# LPC5411x register map
Vendor: nxp.com; File version: 1.2
CPU: CM4 r0p1, little endian, MPU, FPU, VTOR, vendor SysTick, 3 interrupt priority bits
Registers are 32-bit, read-write, reset 0x0 unless marked. A register's access mark holds for its fields unless they carry their own. Offsets are from the block's base; [hi:lo] are bit positions; 'fields as' and 'values as' point back to an identical list.

## USART0 — LPC5411x USARTs
Base 0x40086000
Same registers: USART1 0x40087000, USART2 0x40088000, USART3 0x40089000, USART4 0x4008A000, USART7 0x40096000, USART5 0x40096000, USART6 0x40096000
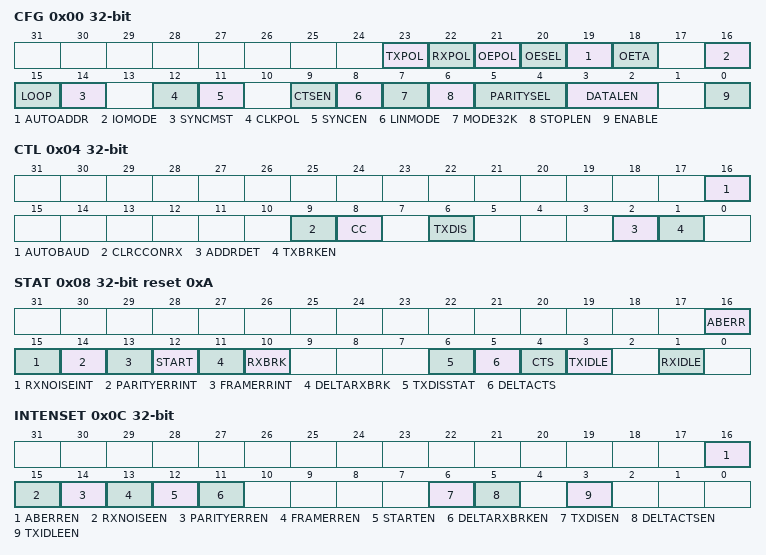
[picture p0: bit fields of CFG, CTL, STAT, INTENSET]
0x00 CFG — USART Configuration register. Basic USART configuration settings that typically are not changed during operation.
  [23] TXPOL — Transmit data polarity.
    0=STANDARD (Standard. The TX signal is sent out without change. This means that the TX rest value is 1, start bit is 0, data is not inverted, and the stop bit is 1.); 1=INVERTED (Inverted. The TX signal is inverted by the USART before being sent out. This means that the TX rest value is 0, start bit is 1, data is inverted, and the stop bit is 0.)
  [22] RXPOL — Receive data polarity.
    0=STANDARD (Standard. The RX signal is used as it arrives from the pin. This means that the RX rest value is 1, start bit is 0, data is not inverted, and the stop bit is 1.); 1=INVERTED (Inverted. The RX signal is inverted before being used by the USART. This means that the RX rest value is 0, start bit is 1, data is inverted, and the stop bit is 0.)
  [21] OEPOL — Output Enable Polarity.
    0=LOW (Low. If selected by OESEL, the output enable is active low.); 1=HIGH (High. If selected by OESEL, the output enable is active high.)
  [20] OESEL — Output Enable Select.
    0=STANDARD (Standard. The RTS signal is used as the standard flow control function.); 1=RS_485 (RS-485. The RTS signal configured to provide an output enable signal to control an RS-485 transceiver.)
  [19] AUTOADDR — Automatic Address matching enable.
    0=DISABLED (Disabled. When addressing is enabled by ADDRDET, address matching is done by software. This provides the possibility of versatile addressing (e.g. respond to more than one address).); 1=ENABLED (Enabled. When addressing is enabled by ADDRDET, address matching is done by hardware, using the value in the ADDR register as the address to match.)
  [18] OETA — Output Enable Turnaround time enable for RS-485 operation.
    0=DISABLED (Disabled. If selected by OESEL, the Output Enable signal deasserted at the end of the last stop bit of a transmission.); 1=ENABLED (Enabled. If selected by OESEL, the Output Enable signal remains asserted for one character time after the end of the last stop bit of a transmission. OE will also remain asserted if another transmit begins before it is deasserted.)
  [16] IOMODE — I/O output mode.
    0=STANDARD (Standard. USART output and input operate in standard fashion.); 1=IRDA (IrDA. USART output and input operate in IrDA mode.)
  [15] LOOP — Selects data loopback mode.
    0=NORMAL (Normal operation.); 1=LOOPBACK (Loopback mode. This provides a mechanism to perform diagnostic loopback testing for USART data. Serial data from the transmitter (Un_TXD) is connected internally to serial input of the receive (Un_RXD). Un_TXD and Un_RTS activity will also appear on external pins if these functions are configured to appear on device pins. The receiver RTS signal is also looped back to CTS and performs flow control if enabled by CTSEN.)
  [14] SYNCMST — Synchronous mode Master select.
    0=SLAVE (Slave. When synchronous mode is enabled, the USART is a slave.); 1=MASTER (Master. When synchronous mode is enabled, the USART is a master.)
  [12] CLKPOL — Selects the clock polarity and sampling edge of received data in synchronous mode.
    0=FALLING_EDGE (Falling edge. Un_RXD is sampled on the falling edge of SCLK.); 1=RISING_EDGE (Rising edge. Un_RXD is sampled on the rising edge of SCLK.)
  [11] SYNCEN — Selects synchronous or asynchronous operation.
    0=ASYNCHRONOUS_MODE; 1=SYNCHRONOUS_MODE
  [9] CTSEN — CTS Enable. Determines whether CTS is used for flow control. CTS can be from the input pin, or from the USART's own RTS if loopback mode is enabled.
    0=DISABLED (No flow control. The transmitter does not receive any automatic flow control signal.); 1=ENABLED (Flow control enabled. The transmitter uses the CTS input (or RTS output in loopback mode) for flow control purposes.)
  [8] LINMODE — LIN break mode enable.
    0=DISABLED (Disabled. Break detect and generate is configured for normal operation.); 1=ENABLED (Enabled. Break detect and generate is configured for LIN bus operation.)
  [7] MODE32K — Selects standard or 32 kHz clocking mode.
    0=DISABLED (Disabled. USART uses standard clocking.); 1=ENABLED (Enabled. USART uses the 32 kHz clock from the RTC oscillator as the clock source to the BRG, and uses a special bit clocking scheme.)
  [6] STOPLEN — Number of stop bits appended to transmitted data. Only a single stop bit is required for received data.
    0=1_BIT (1 stop bit.); 1=2_BITS (2 stop bits. This setting should only be used for asynchronous communication.)
  [5:4] PARITYSEL — Selects what type of parity is used by the USART.
    0=NO_PARITY; 2=EVEN_PARITY (Even parity. Adds a bit to each character such that the number of 1s in a transmitted character is even, and the number of 1s in a received character is expected to be even.); 3=ODD_PARITY (Odd parity. Adds a bit to each character such that the number of 1s in a transmitted character is odd, and the number of 1s in a received character is expected to be odd.)
  [3:2] DATALEN — Selects the data size for the USART.
    0=7_BIT (7 bit Data length.); 1=8_BIT (8 bit Data length.); 2=9_BIT (9 bit data length. The 9th bit is commonly used for addressing in multidrop mode. See the ADDRDET bit in the CTL register.)
  [0] ENABLE — USART Enable.
    0=DISABLED (Disabled. The USART is disabled and the internal state machine and counters are reset. While Enable = 0, all USART interrupts and DMA transfers are disabled. When Enable is set again, CFG and most other control bits remain unchanged. When re-enabled, the USART will immediately be ready to transmit because the transmitter has been reset and is therefore available.); 1=ENABLED (Enabled. The USART is enabled for operation.)
0x04 CTL — USART Control register. USART control settings that are more likely to change during operation.
  [16] AUTOBAUD — Autobaud enable.
    0=DISABLED (Disabled. USART is in normal operating mode.); 1=ENABLED (Enabled. USART is in autobaud mode. This bit should only be set when the USART receiver is idle. The first start bit of RX is measured and used the update the BRG register to match the received data rate. AUTOBAUD is cleared once this process is complete, or if there is an AERR.)
  [9] CLRCCONRX — Clear Continuous Clock.
    0=NO_EFFECT (No effect. No effect on the CC bit.); 1=AUTO_CLEAR (Auto-clear. The CC bit is automatically cleared when a complete character has been received. This bit is cleared at the same time.)
  [8] CC — Continuous Clock generation. By default, SCLK is only output while data is being transmitted in synchronous mode.
    0=CLOCK_ON_CHARACTER (Clock on character. In synchronous mode, SCLK cycles only when characters are being sent on Un_TXD or to complete a character that is being received.); 1=CONTINOUS_CLOCK (Continuous clock. SCLK runs continuously in synchronous mode, allowing characters to be received on Un_RxD independently from transmission on Un_TXD).)
  [6] TXDIS — Transmit Disable.
    0=ENABLED (Not disabled. USART transmitter is not disabled.); 1=DISABLED (Disabled. USART transmitter is disabled after any character currently being transmitted is complete. This feature can be used to facilitate software flow control.)
  [2] ADDRDET — Enable address detect mode.
    0=DISABLED (Disabled. The USART presents all incoming data.); 1=ENABLED (Enabled. The USART receiver ignores incoming data that does not have the most significant bit of the data (typically the 9th bit) = 1. When the data MSB bit = 1, the receiver treats the incoming data normally, generating a received data interrupt. Software can then check the data to see if this is an address that should be handled. If it is, the ADDRDET bit is cleared by software and further incoming data is handled normally.)
  [1] TXBRKEN — Break Enable.
    0=NORMAL (Normal operation.); 1=CONTINOUS (Continuous break. Continuous break is sent immediately when this bit is set, and remains until this bit is cleared. A break may be sent without danger of corrupting any currently transmitting character if the transmitter is first disabled (TXDIS in CTL is set) and then waiting for the transmitter to be disabled (TXDISINT in STAT = 1) before writing 1 to TXBRKEN.)
0x08 STAT reset 0xA (reset mask 0x45A) — USART Status register. The complete status value can be read here. Writing ones clears some bits in the register. Some bits can be cleared by writing a 1 to them.
  [16] ABERR wo — Auto baud Error. An auto baud error can occur if the BRG counts to its limit before the end of the start bit that is being measured, essentially an auto baud time-out.
  [15] RXNOISEINT wo — Received Noise interrupt flag. Three samples of received data are taken in order to determine the value of each received data bit, except in synchronous mode. This acts as a noise filter if one sample disagrees. This flag is set when a received data bit contains one disagreeing sample. This could indicate line noise, a baud rate or character format mismatch, or loss of synchronization during data reception.
  [14] PARITYERRINT wo — Parity Error interrupt flag. This flag is set when a parity error is detected in a received character.
  [13] FRAMERRINT wo — Framing Error interrupt flag. This flag is set when a character is received with a missing stop bit at the expected location. This could be an indication of a baud rate or configuration mismatch with the transmitting source.
  [12] START wo — This bit is set when a start is detected on the receiver input. Its purpose is primarily to allow wake-up from Deep-sleep or Power-down mode immediately when a start is detected. Cleared by software.
  [11] DELTARXBRK wo — This bit is set when a change in the state of receiver break detection occurs. Cleared by software.
  [10] RXBRK ro — Received Break. This bit reflects the current state of the receiver break detection logic. It is set when the Un_RXD pin remains low for 16 bit times. Note that FRAMERRINT will also be set when this condition occurs because the stop bit(s) for the character would be missing. RXBRK is cleared when the Un_RXD pin goes high.
  [6] TXDISSTAT ro — Transmitter Disabled Status flag. When 1, this bit indicates that the USART transmitter is fully idle after being disabled via the TXDIS bit in the CFG register (TXDIS = 1).
  [5] DELTACTS wo — This bit is set when a change in the state is detected for the CTS flag above. This bit is cleared by software.
  [4] CTS ro — This bit reflects the current state of the CTS signal, regardless of the setting of the CTSEN bit in the CFG register. This will be the value of the CTS input pin unless loopback mode is enabled.
  [3] TXIDLE ro — Transmitter Idle. When 0, indicates that the transmitter is currently in the process of sending data.When 1, indicate that the transmitter is not currently in the process of sending data.
  [1] RXIDLE ro — Receiver Idle. When 0, indicates that the receiver is currently in the process of receiving data. When 1, indicates that the receiver is not currently in the process of receiving data.
0x0C INTENSET — Interrupt Enable read and Set register for USART (not FIFO) status. Contains individual interrupt enable bits for each potential USART interrupt. A complete value may be read from this register. Writing a 1 to any implemented bit position causes that bit to be set.
  [16] ABERREN — When 1, enables an interrupt when an auto baud error occurs.
  [15] RXNOISEEN — When 1, enables an interrupt when noise is detected. See description of the RXNOISEINT bit in Table 354.
  [14] PARITYERREN — When 1, enables an interrupt when a parity error has been detected.
  [13] FRAMERREN — When 1, enables an interrupt when a framing error has been detected.
  [12] STARTEN — When 1, enables an interrupt when a received start bit has been detected.
  [11] DELTARXBRKEN — When 1, enables an interrupt when a change of state has occurred in the detection of a received break condition (break condition asserted or deasserted).
  [6] TXDISEN — When 1, enables an interrupt when the transmitter is fully disabled as indicated by the TXDISINT flag in STAT. See description of the TXDISINT bit for details.
  [5] DELTACTSEN — When 1, enables an interrupt when there is a change in the state of the CTS input.
  [3] TXIDLEEN — When 1, enables an interrupt when the transmitter becomes idle (TXIDLE = 1).
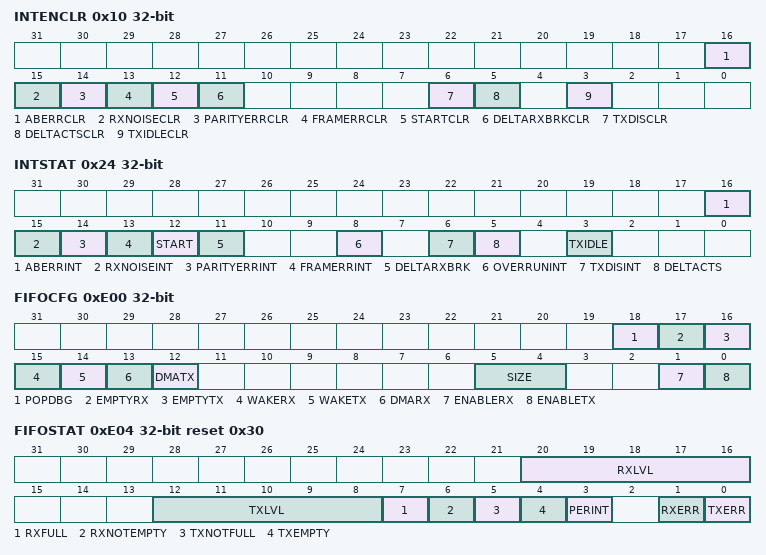
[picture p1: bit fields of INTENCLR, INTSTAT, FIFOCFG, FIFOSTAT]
0x10 INTENCLR reset not defined — Interrupt Enable Clear register. Allows clearing any combination of bits in the INTENSET register. Writing a 1 to any implemented bit position causes the corresponding bit to be cleared.
  [16] ABERRCLR wo — Writing 1 clears the corresponding bit in the INTENSET register.
  [15] RXNOISECLR wo — Writing 1 clears the corresponding bit in the INTENSET register.
  [14] PARITYERRCLR wo — Writing 1 clears the corresponding bit in the INTENSET register.
  [13] FRAMERRCLR wo — Writing 1 clears the corresponding bit in the INTENSET register.
  [12] STARTCLR wo — Writing 1 clears the corresponding bit in the INTENSET register.
  [11] DELTARXBRKCLR wo — Writing 1 clears the corresponding bit in the INTENSET register.
  [6] TXDISCLR wo — Writing 1 clears the corresponding bit in the INTENSET register.
  [5] DELTACTSCLR wo — Writing 1 clears the corresponding bit in the INTENSET register.
  [3] TXIDLECLR wo — Writing 1 clears the corresponding bit in the INTENSET register.
0x20 BRG — Baud Rate Generator register. 16-bit integer baud rate divisor value.
  [15:0] BRGVAL — This value is used to divide the USART input clock to determine the baud rate, based on the input clock from the FRG. 0 = FCLK is used directly by the USART function. 1 = FCLK is divided by 2 before use by the USART function. 2 = FCLK is divided by 3 before use by the USART function. 0xFFFF = FCLK is divided by 65,536 before use by the USART function.
0x24 INTSTAT — Interrupt status register. Reflects interrupts that are currently enabled.
  [16] ABERRINT ro — Auto baud Error Interrupt flag.
  [15] RXNOISEINT ro — Received Noise interrupt flag.
  [14] PARITYERRINT ro — Parity Error interrupt flag.
  [13] FRAMERRINT ro — Framing Error interrupt flag.
  [12] START ro — This bit is set when a start is detected on the receiver input.
  [11] DELTARXBRK ro — This bit is set when a change in the state of receiver break detection occurs.
  [8] OVERRUNINT ro — Overrun Error interrupt flag.
  [6] TXDISINT ro — Transmitter Disabled Interrupt flag.
  [5] DELTACTS ro — This bit is set when a change in the state of the CTS input is detected.
  [3] TXIDLE ro — Transmitter Idle status.
0x28 OSR reset 0xF — Oversample selection register for asynchronous communication.
  [3:0] OSRVAL — Oversample Selection Value. 0 to 3 = not supported 0x4 = 5 function clocks are used to transmit and receive each data bit. 0x5 = 6 function clocks are used to transmit and receive each data bit. 0xF= 16 function clocks are used to transmit and receive each data bit.
0x2C ADDR — Address register for automatic address matching.
  [7:0] ADDRESS — 8-bit address used with automatic address matching. Used when address detection is enabled (ADDRDET in CTL = 1) and automatic address matching is enabled (AUTOADDR in CFG = 1).
0xE00 FIFOCFG — FIFO configuration and enable register.
  [18] POPDBG — Pop FIFO for debug reads.
    0=DO_NOT_POP (Debug reads of the FIFO do not pop the FIFO.); 1=POP (A debug read will cause the FIFO to pop.)
  [17] EMPTYRX — Empty command for the receive FIFO. When a 1 is written to this bit, the RX FIFO is emptied.
  [16] EMPTYTX — Empty command for the transmit FIFO. When a 1 is written to this bit, the TX FIFO is emptied.
  [15] WAKERX — Wake-up for receive FIFO level. This allows the device to be woken from reduced power modes (up to power-down, as long as the peripheral function works in that power mode) without enabling the TXLVL interrupt. Only DMA wakes up, processes data, and goes back to sleep. The CPU will remain stopped until woken by another cause, such as DMA completion. See Hardware Wake-up control register.
    0=DISABLED (Only enabled interrupts will wake up the device form reduced power modes.); 1=ENABLED (A device wake-up for DMA will occur if the receive FIFO level reaches the value specified by RXLVL in FIFOTRIG, even when the RXLVL interrupt is not enabled.)
  [14] WAKETX — Wake-up for transmit FIFO level. This allows the device to be woken from reduced power modes (up to power-down, as long as the peripheral function works in that power mode) without enabling the TXLVL interrupt. Only DMA wakes up, processes data, and goes back to sleep. The CPU will remain stopped until woken by another cause, such as DMA completion. See Hardware Wake-up control register.
    0=DISABLED (Only enabled interrupts will wake up the device form reduced power modes.); 1=ENABLED (A device wake-up for DMA will occur if the transmit FIFO level reaches the value specified by TXLVL in FIFOTRIG, even when the TXLVL interrupt is not enabled.)
  [13] DMARX — DMA configuration for receive.
    0=DISABLED (DMA is not used for the receive function.); 1=ENABLED (Trigger DMA for the receive function if the FIFO is not empty. Generally, data interrupts would be disabled if DMA is enabled.)
  [12] DMATX — DMA configuration for transmit.
    0=DISABLED (DMA is not used for the transmit function.); 1=ENABLED (Trigger DMA for the transmit function if the FIFO is not full. Generally, data interrupts would be disabled if DMA is enabled.)
  [5:4] SIZE ro — FIFO size configuration. This is a read-only field. 0x0 = FIFO is configured as 16 entries of 8 bits. 0x1, 0x2, 0x3 = not applicable to USART.
  [1] ENABLERX — Enable the receive FIFO.
    0=DISABLED (The receive FIFO is not enabled.); 1=ENABLED (The receive FIFO is enabled.)
  [0] ENABLETX — Enable the transmit FIFO.
    0=DISABLED (The transmit FIFO is not enabled.); 1=ENABLED (The transmit FIFO is enabled.)
0xE04 FIFOSTAT reset 0x30 — FIFO status register.
  [20:16] RXLVL ro — Receive FIFO current level. A 0 means the RX FIFO is currently empty, and the RXFULL and RXNOTEMPTY flags will be 0. Other values tell how much data is actually in the RX FIFO at the point where the read occurs. If the RX FIFO is full, the RXFULL and RXNOTEMPTY flags will be 1.
  [12:8] TXLVL ro — Transmit FIFO current level. A 0 means the TX FIFO is currently empty, and the TXEMPTY and TXNOTFULL flags will be 1. Other values tell how much data is actually in the TX FIFO at the point where the read occurs. If the TX FIFO is full, the TXEMPTY and TXNOTFULL flags will be 0.
  [7] RXFULL ro — Receive FIFO full. When 1, the receive FIFO is full. Data needs to be read out to prevent the peripheral from causing an overflow.
  [6] RXNOTEMPTY ro — Receive FIFO not empty. When 1, the receive FIFO is not empty, so data can be read. When 0, the receive FIFO is empty.
  [5] TXNOTFULL ro — Transmit FIFO not full. When 1, the transmit FIFO is not full, so more data can be written. When 0, the transmit FIFO is full and another write would cause it to overflow.
  [4] TXEMPTY ro — Transmit FIFO empty. When 1, the transmit FIFO is empty. The peripheral may still be processing the last piece of data.
  [3] PERINT ro — Peripheral interrupt. When 1, this indicates that the peripheral function has asserted an interrupt. The details can be found by reading the peripheral's STAT register.
  [1] RXERR — RX FIFO error. Will be set if a receive FIFO overflow occurs, caused by software or DMA not emptying the FIFO fast enough. Cleared by writing a 1 to this bit.
  [0] TXERR — TX FIFO error. Will be set if a transmit FIFO error occurs. This could be an overflow caused by pushing data into a full FIFO, or by an underflow if the FIFO is empty when data is needed. Cleared by writing a 1 to this bit.
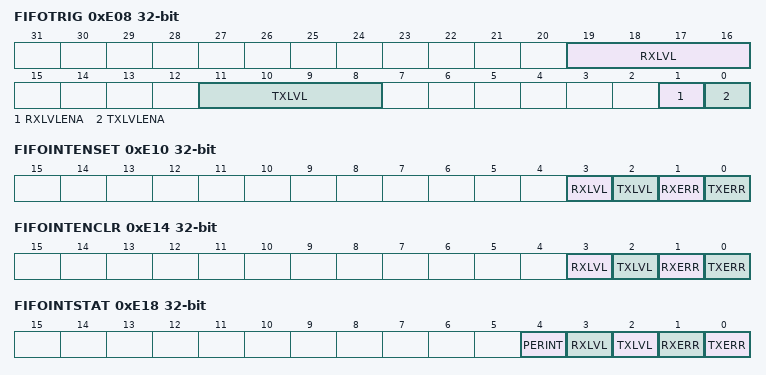
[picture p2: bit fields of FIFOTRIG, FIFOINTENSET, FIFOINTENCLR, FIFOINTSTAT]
0xE08 FIFOTRIG — FIFO trigger settings for interrupt and DMA request.
  [19:16] RXLVL — Receive FIFO level trigger point. The RX FIFO level is checked when a new piece of data is received. This field is used only when RXLVLENA = 1. If enabled to do so, the FIFO level can wake up the device just enough to perform DMA, then return to the reduced power mode. See Hardware Wake-up control register. 0 = trigger when the RX FIFO has received one entry (is no longer empty). 1 = trigger when the RX FIFO has received two entries. 15 = trigger when the RX FIFO has received 16 entries (has become full).
  [11:8] TXLVL — Transmit FIFO level trigger point. This field is used only when TXLVLENA = 1. If enabled to do so, the FIFO level can wake up the device just enough to perform DMA, then return to the reduced power mode. See Hardware Wake-up control register. 0 = trigger when the TX FIFO becomes empty. 1 = trigger when the TX FIFO level decreases to one entry. 15 = trigger when the TX FIFO level decreases to 15 entries (is no longer full).
  [1] RXLVLENA — Receive FIFO level trigger enable. This trigger will become an interrupt if enabled in FIFOINTENSET, or a DMA trigger if DMARX in FIFOCFG is set.
    0=DISABLED (Receive FIFO level does not generate a FIFO level trigger.); 1=ENABLED (An trigger will be generated if the receive FIFO level reaches the value specified by the RXLVL field in this register.)
  [0] TXLVLENA — Transmit FIFO level trigger enable. This trigger will become an interrupt if enabled in FIFOINTENSET, or a DMA trigger if DMATX in FIFOCFG is set.
    0=DISABLED (Transmit FIFO level does not generate a FIFO level trigger.); 1=ENABLED (An trigger will be generated if the transmit FIFO level reaches the value specified by the TXLVL field in this register.)
0xE10 FIFOINTENSET — FIFO interrupt enable set (enable) and read register.
  [3] RXLVL — Determines whether an interrupt occurs when a the receive FIFO reaches the level specified by the TXLVL field in the FIFOTRIG register.
    0=DISABLED (No interrupt will be generated based on the RX FIFO level.); 1=ENABLED (If RXLVLENA in the FIFOTRIG register = 1, an interrupt will be generated when the when the RX FIFO level increases to the level specified by RXLVL in the FIFOTRIG register.)
  [2] TXLVL — Determines whether an interrupt occurs when a the transmit FIFO reaches the level specified by the TXLVL field in the FIFOTRIG register.
    0=DISABLED (No interrupt will be generated based on the TX FIFO level.); 1=ENABLED (If TXLVLENA in the FIFOTRIG register = 1, an interrupt will be generated when the TX FIFO level decreases to the level specified by TXLVL in the FIFOTRIG register.)
  [1] RXERR — Determines whether an interrupt occurs when a receive error occurs, based on the RXERR flag in the FIFOSTAT register.
    0=DISABLED (No interrupt will be generated for a receive error.); 1=ENABLED (An interrupt will be generated when a receive error occurs.)
  [0] TXERR — Determines whether an interrupt occurs when a transmit error occurs, based on the TXERR flag in the FIFOSTAT register.
    0=DISABLED (No interrupt will be generated for a transmit error.); 1=ENABLED (An interrupt will be generated when a transmit error occurs.)
0xE14 FIFOINTENCLR — FIFO interrupt enable clear (disable) and read register.
  [3] RXLVL — Writing one clears the corresponding bits in the FIFOINTENSET register.
  [2] TXLVL — Writing one clears the corresponding bits in the FIFOINTENSET register.
  [1] RXERR — Writing one clears the corresponding bits in the FIFOINTENSET register.
  [0] TXERR — Writing one clears the corresponding bits in the FIFOINTENSET register.
0xE18 FIFOINTSTAT — FIFO interrupt status register.
  [4] PERINT ro — Peripheral interrupt.
  [3] RXLVL ro — Receive FIFO level interrupt.
  [2] TXLVL ro — Transmit FIFO level interrupt.
  [1] RXERR ro — RX FIFO error.
  [0] TXERR ro — TX FIFO error.
0xE20 FIFOWR 9-bit reset not defined — FIFO write data.
  [8:0] TXDATA wo — Transmit data to the FIFO.
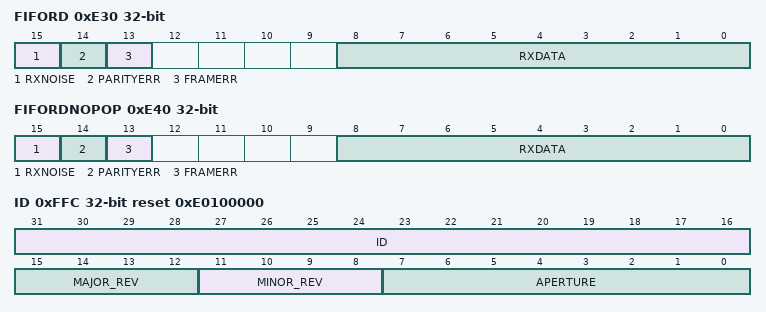
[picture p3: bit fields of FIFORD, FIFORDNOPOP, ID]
0xE30 FIFORD — FIFO read data.
  [15] RXNOISE ro — Received Noise flag. See description of the RxNoiseInt bit in Table 354.
  [14] PARITYERR ro — Parity Error status flag. This bit reflects the status for the data it is read along with from the FIFO. This bit will be set when a parity error is detected in a received character.
  [13] FRAMERR ro — Framing Error status flag. This bit reflects the status for the data it is read along with from the FIFO, and indicates that the character was received with a missing stop bit at the expected location. This could be an indication of a baud rate or configuration mismatch with the transmitting source.
  [8:0] RXDATA ro — Received data from the FIFO. The number of bits used depends on the DATALEN and PARITYSEL settings.
0xE40 FIFORDNOPOP — FIFO data read with no FIFO pop.
  fields as FIFORD
0xFFC ID reset 0xE0100000 — USART module Identification. This value appears in the shared Flexcomm peripheral ID register when USART is selected.
  [31:16] ID ro — Unique module identifier for this IP block.
  [15:12] MAJOR_REV ro — Major revision of module implementation, starting at 0. There may not be software compatibility between major revisions.
  [11:8] MINOR_REV ro — Minor revision of module implementation, starting at 0. Minor revision of module implementation, starting at 0. Software compatibility is expected between minor revisions.
  [7:0] APERTURE ro — Aperture: encoded as (aperture size/4K) -1, so 0x00 means a 4K aperture.
